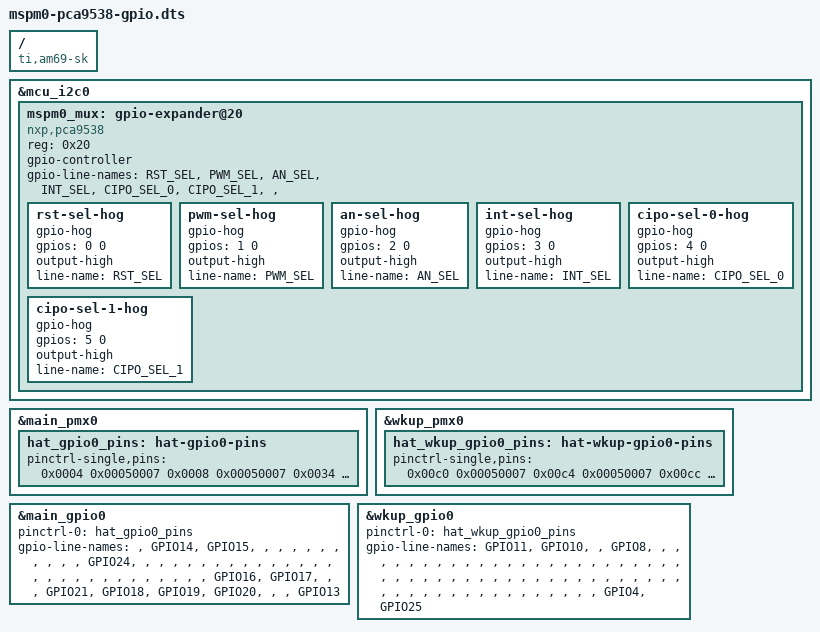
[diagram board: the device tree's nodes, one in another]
/dts-v1/;
/plugin/;

/ {
	compatible = "ti,am69-sk", "ti,j784s4";

	fragment@0 {
		/* SK-AM69 40-pin expansion header pins 3/5 are MCU_I2C0. */
		target = <&mcu_i2c0>;
		__overlay__ {
			#address-cells = <1>;
			#size-cells = <0>;

			mspm0_mux: gpio-expander@20 {
				compatible = "nxp,pca9538";
				reg = <0x20>;
				gpio-controller;
				#gpio-cells = <2>;
				gpio-line-names =
					"RST_SEL",
					"PWM_SEL",
					"AN_SEL",
					"INT_SEL",
					"CIPO_SEL_0",
					"CIPO_SEL_1",
					"",
					"";
				status = "okay";

				/* TI AM69 SK-EVM audio-board routing defaults. */
				rst-sel-hog {
					gpio-hog;
					gpios = <0 0>;
					output-high;
					line-name = "RST_SEL";
				};

				pwm-sel-hog {
					gpio-hog;
					gpios = <1 0>;
					output-high;
					line-name = "PWM_SEL";
				};

				an-sel-hog {
					gpio-hog;
					gpios = <2 0>;
					output-high;
					line-name = "AN_SEL";
				};

				int-sel-hog {
					gpio-hog;
					gpios = <3 0>;
					output-high;
					line-name = "INT_SEL";
				};

				cipo-sel-0-hog {
					gpio-hog;
					gpios = <4 0>;
					output-high;
					line-name = "CIPO_SEL_0";
				};

				cipo-sel-1-hog {
					gpio-hog;
					gpios = <5 0>;
					output-high;
					line-name = "CIPO_SEL_1";
				};
			};
		};
	};

	fragment@1 {
		target = <&main_pmx0>;
		__overlay__ {
			hat_gpio0_pins: hat-gpio0-pins {
				pinctrl-single,pins = <
					0x0004 0x00050007 /* HAT pin 8 / GPIO14 / AG36 / GPIO0_1 input */
					0x0008 0x00050007 /* HAT pin 10 / GPIO15 / AJ33 / GPIO0_2 input */
					0x0034 0x00050007 /* HAT pin 18 / GPIO24 / AJ34 / GPIO0_13 input */
					0x00a8 0x00050007 /* HAT pin 11 / GPIO17 / AF34 / GPIO0_42 input */
					0x00b4 0x00050007 /* HAT pin 40 / GPIO21 / AL34 / GPIO0_45 input */
					0x00b8 0x00050007 /* HAT pin 12 / GPIO18 / AC34 / GPIO0_46 input */
					0x00bc 0x00050007 /* HAT pin 35 / GPIO19 / AD33 / GPIO0_47 input */
					0x00c0 0x00050007 /* HAT pin 38 / GPIO20 / AD38 / GPIO0_48 input */
					0x00cc 0x00050007 /* HAT pin 33 / GPIO13 / AM37 / GPIO0_51 input */
				>;
			};
		};
	};

	fragment@2 {
		target = <&wkup_pmx0>;
		__overlay__ {
			hat_wkup_gpio0_pins: hat-wkup-gpio0-pins {
				pinctrl-single,pins = <
					0x00c0 0x00050007 /* HAT pin 23 / GPIO11 / H38 / WKUP_GPIO0_0 input */
					0x00c4 0x00050007 /* HAT pin 19 / GPIO10 / J34 / WKUP_GPIO0_1 input */
					0x00cc 0x00050007 /* HAT pin 24 / GPIO8 / J36 / WKUP_GPIO0_3 input */
					0x0180 0x00050007 /* HAT pin 7 / GPIO4 / N34 / WKUP_GPIO0_66 input */
					0x0184 0x00040007 /* HAT pin 22 / GPIO25 / M34 / WKUP_GPIO0_67 input, pull-down */
				>;
			};
		};
	};

	fragment@3 {
		target = <&main_gpio0>;
		__overlay__ {
			pinctrl-names = "default";
			pinctrl-0 = <&hat_gpio0_pins>;
			gpio-line-names = "", "GPIO14", "GPIO15", "", "", "", "", "", "", "",
				"", "", "", "GPIO24", "", "", "", "", "", "",
				"", "", "", "", "", "", "", "", "", "",
				"", "", "", "", "", "", "", "", "", "",
				"", "GPIO16", "GPIO17", "", "", "GPIO21", "GPIO18",
				"GPIO19", "GPIO20", "", "", "GPIO13";
			status = "okay";
		};
	};

	fragment@4 {
		target = <&wkup_gpio0>;
		__overlay__ {
			pinctrl-names = "default";
			pinctrl-0 = <&hat_wkup_gpio0_pins>;
			gpio-line-names = "GPIO11", "GPIO10", "", "GPIO8", "", "", "", "", "", "",
				"", "", "", "", "", "", "", "", "", "",
				"", "", "", "", "", "", "", "", "", "",
				"", "", "", "", "", "", "", "", "", "",
				"", "", "", "", "", "", "", "", "", "",
				"", "", "", "", "", "", "", "", "", "",
				"", "", "", "", "", "", "GPIO4", "GPIO25";
			status = "okay";
		};
	};
};
